# RA register map
Vendor: Renesas; Series: All Chips; File version: x.xx
Registers are 32-bit, read-write, reset 0x0 unless marked. A register's access mark holds for its fields unless they carry their own. Offsets are from the block's base; [hi:lo] are bit positions.

## R_CPSCU — CPU System Security Control Unit
Base 0x40008000
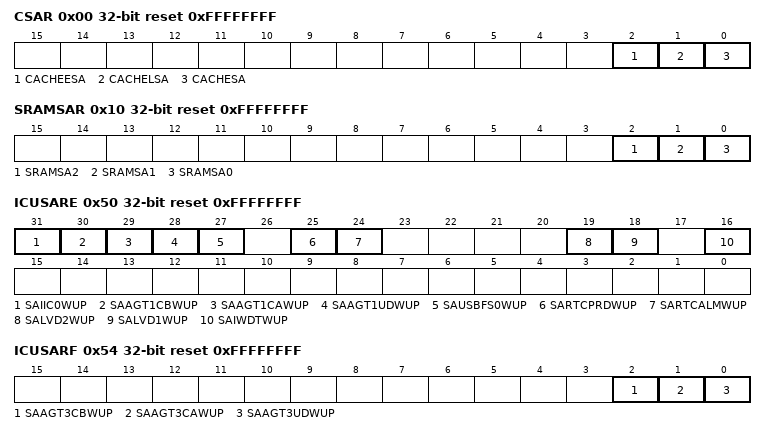
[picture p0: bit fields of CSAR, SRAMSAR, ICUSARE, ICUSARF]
0x00 CSAR reset 0xFFFFFFFF — Cache Security Attribution Register
  [all] fields
    0=Secure; 1=Non-secure
  [2] CACHEESA — Security Attributes of Registers for Cache Error
  [1] CACHELSA — Security Attributes of Registers for Cache Line Configuration
  [0] CACHESA — Security Attributes of Registers for Cache Control
0x10 SRAMSAR reset 0xFFFFFFFF — SRAM Security Attribution Register
  [all] fields
    0=Secure; 1=Nonsecure
  [2] SRAMSA2 — Security attributes of registers for ECC Relation
  [1] SRAMSA1 — Security attributes of registers for SRAM Protection 2
  [0] SRAMSA0 — Security attributes of registers for SRAM Protection
0x14 STBRAMSAR reset 0xFFFFFFF0 — Standby RAM memory Security Attribution Register
  [3:0] NSBSTBR — Security attributes of each region for Standby RAM
    0=Region7-0 are all Secure; 1=Region7 is Non-secure. Region6-0 are Secure; 2=Region7-6 are Non-secure. Region5-0 are Secure.; 3=Region7-5 are Non-secure. Region4-0 are Secure.; 4=Region7-4 are Non-secure. Region 3-0 are Secure.; 5=Region7-3 are Non-secure. Region 2-0 are Secure.; 6=Region7-2 are Non-secure. Region 1-0 are Secure.; 7=Region7-1 are Non-Secure. Region0 is Secure.; other=Others (Region7-0 are all Non-Secure.)
0x30 DTCSAR reset 0xFFFFFFFF — DTC Controller Security Attribution Register
  [0] DTCSTSA — DTC Security Attribution
    0=Secure; 1=Non-Secure
0x34 DMACSAR reset 0xFFFFFFFF — DMAC Controller Security Attribution Register
  [0] DMASTSA — DMAST Security Attribution
    0=Secure; 1=Non-secure
0x40 ICUSARA reset 0xFFFFFFFF — ICU Security Attribution Register A
  [15:0] SAIRQCRn — Security Attributes of registers for the IRQCRn registers
0x44 ICUSARB reset 0xFFFFFFFF — ICU Security Attribution Register B
  [0] SANMI — Security Attributes of nonmaskable interrupt
0x48 ICUSARC reset 0xFFFFFFFF — ICU Security Attribution Register C
  [7:0] SADMACn — Security Attributes of registers for DMAC channel
0x4C ICUSARD reset 0xFFFFFFFF — ICU Security Attribution Register D
  [0] SASELSR0 — Security Attributes of registers for SELSR0
0x50 ICUSARE reset 0xFFFFFFFF — ICU Security Attribution Register E
  [31] SAIIC0WUP — Security Attributes of registers for WUPEN0.b 31
  [30] SAAGT1CBWUP — Security Attributes of registers for WUPEN0.b 30
  [29] SAAGT1CAWUP — Security Attributes of registers for WUPEN0.b 29
  [28] SAAGT1UDWUP — Security Attributes of registers for WUPEN0.b 28
  [27] SAUSBFS0WUP — Security Attributes of registers for WUPEN0.b 27
  [25] SARTCPRDWUP — Security Attributes of registers for WUPEN0.b 25
  [24] SARTCALMWUP — Security Attributes of registers for WUPEN0.b 24
  [19] SALVD2WUP — Security Attributes of registers for WUPEN0.b 19
  [18] SALVD1WUP — Security Attributes of registers for WUPEN0.b 18
  [16] SAIWDTWUP — Security Attributes of registers for WUPEN0.b 16
0x54 ICUSARF reset 0xFFFFFFFF — ICU Security Attribution Register F
  [2] SAAGT3CBWUP — Security Attributes of registers for WUPEN1.b 2
  [1] SAAGT3CAWUP — Security Attributes of registers for WUPEN1.b 1
  [0] SAAGT3UDWUP — Security Attributes of registers for WUPEN1.b 0
0x70 ICUSARG reset 0xFFFFFFFF — ICU Security Attribution Register G
  [31:0] SAIELSRn — Security Attributes of registers for IELSR31 to IELSR0
0x74 ICUSARH reset 0xFFFFFFFF — ICU Security Attribution Register H
  [31:0] SAIELSRn — Security Attributes of registers for IELSR63 to IELSR32
0x78 ICUSARI reset 0xFFFFFFFF — ICU Security Attribution Register I
  [31:0] SAIELSRn — Security Attributes of registers for IELSR95 to IELSR64
0x100 BUSSARA reset 0xFFFFFFFF — Bus Security Attribution Register A
  [0] BUSSA0 — BUS Security Attribution A0
    0=Secure; 1=Non-Secure
0x104 BUSSARB reset 0xFFFFFFFF — Bus Security Attribution Register B
  [0] BUSSB0 — BUS Security Attribution B0
    0=Secure; 1=Non-Secure
0x130 MMPUSARA reset 0xFFFFFFFF — Master Memory Protection Unit Security Attribution Register A
  [7:0] MMPUAnSA — MMPUAn Security Attribution (n = 0 to 7)
    0=Secure; 1=Non-Secure
0x134 MMPUSARB reset 0xFFFFFFFF — Master Memory Protection Unit Security Attribution Register B
  [0] MMPUB0SA — MMPUB0 Security Attribution
    0=Secure; 1=Non-Secure
0x1B0 CPUDSAR reset 0xFFFFFFFF — CPU Debug Security Attribution Register
  [0] CPUDSA0 — CPU Debug Security Attribution 0
    0=Secure; 1=Non-secure
